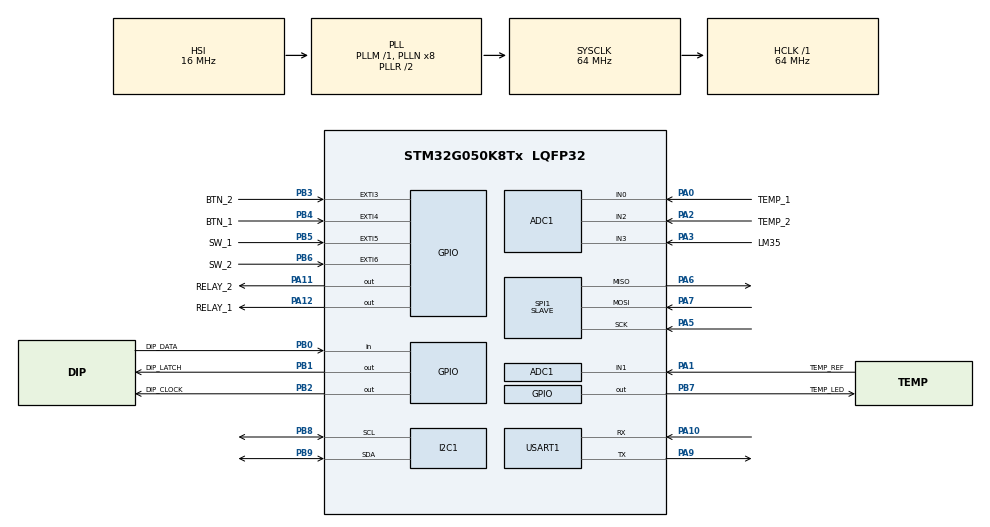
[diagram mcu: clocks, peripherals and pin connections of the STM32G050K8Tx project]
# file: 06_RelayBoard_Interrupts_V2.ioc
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ADC1.Channel-0\#ChannelRegularConversion=ADC_CHANNEL_0
ADC1.Channel-1\#ChannelRegularConversion=ADC_CHANNEL_1
ADC1.Channel-2\#ChannelRegularConversion=ADC_CHANNEL_2
ADC1.Channel-3\#ChannelRegularConversion=ADC_CHANNEL_3
ADC1.ClockPrescaler=ADC_CLOCK_ASYNC_DIV10
ADC1.NbrOfConversion=4
ADC1.NbrOfConversionFlag=1
ADC1.Rank-0\#ChannelRegularConversion=1
ADC1.Rank-1\#ChannelRegularConversion=2
ADC1.Rank-2\#ChannelRegularConversion=3
ADC1.Rank-3\#ChannelRegularConversion=4
ADC1.SamplingTime-0\#ChannelRegularConversion=ADC_SAMPLINGTIME_COMMON_1
ADC1.SamplingTime-1\#ChannelRegularConversion=ADC_SAMPLINGTIME_COMMON_1
ADC1.SamplingTime-2\#ChannelRegularConversion=ADC_SAMPLINGTIME_COMMON_1
ADC1.SamplingTime-3\#ChannelRegularConversion=ADC_SAMPLINGTIME_COMMON_1
ADC1.SelectedChannel=ADC_CHANNEL_0|ADC_CHANNEL_1|ADC_CHANNEL_2|ADC_CHANNEL_3
ADC1.TriggerFrequencyMode=ADC_TRIGGER_FREQ_LOW
ADC1.master=1
Dma.ADC1.0.Direction=DMA_PERIPH_TO_MEMORY
Dma.ADC1.0.EventEnable=DISABLE
Dma.ADC1.0.Instance=DMA1_Channel1
Dma.ADC1.0.MemDataAlignment=DMA_MDATAALIGN_WORD
Dma.ADC1.0.MemInc=DMA_MINC_ENABLE
Dma.ADC1.0.Mode=DMA_CIRCULAR
Dma.ADC1.0.PeriphDataAlignment=DMA_PDATAALIGN_WORD
Dma.ADC1.0.PeriphInc=DMA_PINC_DISABLE
Dma.ADC1.0.Polarity=HAL_DMAMUX_REQ_GEN_RISING
Dma.ADC1.0.Priority=DMA_PRIORITY_LOW
Dma.ADC1.0.RequestNumber=1
Dma.ADC1.0.SignalID=NONE
Dma.ADC1.0.SyncEnable=DISABLE
Dma.ADC1.0.SyncPolarity=HAL_DMAMUX_SYNC_NO_EVENT
Dma.ADC1.0.SyncRequestNumber=1
Dma.ADC1.0.SyncSignalID=NONE
Dma.Request0=ADC1
I2C1.Timing=0x10B17DB5
Mcu.Family=STM32G0
Mcu.Name=STM32G050K8Tx
Mcu.Package=LQFP32
NVIC.DMA1_Channel1_IRQn=true\:0\:0\:false\:false\:true\:false\:true\:true
NVIC.EXTI2_3_IRQn=true\:0\:0\:true\:false\:true\:true\:true\:true
NVIC.EXTI4_15_IRQn=true\:0\:0\:false\:false\:true\:true\:true\:true
PA0.GPIO_Label=TEMP_1
PA0.Mode=IN0
PA0.Signal=ADC1_IN0
PA1.GPIO_Label=TEMP_REF
PA1.Mode=IN1
PA1.Signal=ADC1_IN1
PA10.Mode=Asynchronous
PA10.Signal=USART1_RX
PA11\ [PA9].GPIO_Label=RELAY_2
PA11\ [PA9].Signal=GPIO_Output
PA12\ [PA10].GPIO_Label=RELAY_1
PA12\ [PA10].Signal=GPIO_Output
PA13.Mode=Serial_Wire
PA13.Signal=SYS_SWDIO
PA14-BOOT0.Mode=Serial_Wire
PA14-BOOT0.Signal=SYS_SWCLK
PA2.GPIO_Label=TEMP_2
PA2.Mode=IN2
PA2.Signal=ADC1_IN2
PA3.GPIO_Label=LM35
PA3.Mode=IN3
PA3.Signal=ADC1_IN3
PA5.Mode=Full_Duplex_Slave
PA5.Signal=SPI1_SCK
PA6.Mode=Full_Duplex_Slave
PA6.Signal=SPI1_MISO
PA7.Mode=Full_Duplex_Slave
PA7.Signal=SPI1_MOSI
PA9.Mode=Asynchronous
PA9.Signal=USART1_TX
PB0.GPIO_Label=DIP_DATA
PB0.Signal=GPIO_Input
PB1.GPIO_Label=DIP_LATCH
PB1.Signal=GPIO_Output
PB2.GPIO_Label=DIP_CLOCK
PB2.Signal=GPIO_Output
PB3.GPIO_Label=BTN_2
PB3.GPIO_ModeDefaultEXTI=GPIO_MODE_IT_FALLING
PB3.Signal=GPXTI3
PB4.GPIO_Label=BTN_1
PB4.GPIO_ModeDefaultEXTI=GPIO_MODE_IT_FALLING
PB4.Signal=GPXTI4
PB5.GPIO_Label=SW_1
PB5.GPIO_ModeDefaultEXTI=GPIO_MODE_IT_RISING_FALLING
PB5.Signal=GPXTI5
PB6.GPIO_Label=SW_2
PB6.GPIO_ModeDefaultEXTI=GPIO_MODE_IT_RISING_FALLING
PB6.Signal=GPXTI6
PB7.GPIO_Label=TEMP_LED
PB7.Signal=GPIO_Output
PB8.Mode=I2C
PB8.Signal=I2C1_SCL
PB9.Mode=I2C
PB9.Signal=I2C1_SDA
PC14-OSC32_IN\ (PC14).Mode=HSE-External-Clock-Source
PC14-OSC32_IN\ (PC14).Signal=RCC_OSC_IN
PC15-OSC32_OUT\ (PC15).Mode=OSC enable
PC15-OSC32_OUT\ (PC15).Signal=RCC_OSC_EN
ProjectManager.HeapSize=0x200
ProjectManager.StackSize=0x400
ProjectManager.TargetToolchain=CMake
RCC.ADCCLockSelection=RCC_ADCCLKSOURCE_HSI
RCC.ADCFreq_Value=16000000
RCC.AHBFreq_Value=64000000
RCC.CortexFreq_Value=64000000
RCC.EXTERNAL_CLOCK_VALUE=48000
RCC.HCLKFreq_Value=64000000
RCC.HSE_VALUE=8000000
RCC.HSI_VALUE=16000000
RCC.LSE_VALUE=32768
RCC.SYSCLKFreq_VALUE=64000000
RCC.SYSCLKSource=RCC_SYSCLKSOURCE_PLLCLK
RCC.VCOOutputFreq_Value=128000000
SPI1.Direction=SPI_DIRECTION_2LINES
SPI1.Mode=SPI_MODE_SLAVE
SPI1.VirtualType=VM_SLAVE
USART1.VirtualMode-Asynchronous=VM_ASYNC
VP_SYS_VS_DBSignals.Mode=DisableDeadBatterySignals
board=custom

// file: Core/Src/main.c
/* USER CODE BEGIN Header */
/**
  ******************************************************************************
  * @file           : main.c
  * @brief          : Main program body
  ******************************************************************************
  * @attention
  *
  * Copyright (c) 2025 STMicroelectronics.
  * All rights reserved.
  *
  * This software is licensed under terms that can be found in the LICENSE file
  * in the root directory of this software component.
  * If no LICENSE file comes with this software, it is provided AS-IS.
  *
  ******************************************************************************
  */
/* USER CODE END Header */
#include "main.h"
#include "adc.h"
#include "dma.h"
#include "i2c.h"
#include "spi.h"
#include "usart.h"
#include "gpio.h"

/* USER CODE BEGIN Includes */

#include "../../Drivers/Utility/config.h"
#include "../../Drivers/Utility/DIPs.h"
#include "../../Drivers/Utility/Inputs.h"

/* USER CODE END Includes */

void SystemClock_Config(void);

int main(void)
{

  /* MCU Configuration--------------------------------------------------------*/

  /* Reset of all peripherals, Initializes the Flash interface and the Systick. */
  HAL_Init();

  /* Configure the system clock */
  SystemClock_Config();

  /* Initialize all configured peripherals */
  MX_GPIO_Init();
  MX_DMA_Init();
  MX_ADC1_Init();
  MX_I2C1_Init();
  MX_SPI1_Init();
  MX_USART1_UART_Init();
  /* USER CODE BEGIN 2 */

  ReadDIPSwitch(&Timers_CfgParam.Relay1_Timer, &Timers_CfgParam.Relay2_Timer);

  /* USER CODE END 2 */

  /* Infinite loop */
  /* USER CODE BEGIN WHILE */
  while (1)
  {

    //HAL_GPIO_TogglePin(TEMP_LED_GPIO_Port, TEMP_LED_Pin);
    HAL_Delay(10);
    /* USER CODE END WHILE */

  }
}

void SystemClock_Config(void)
{
  RCC_OscInitTypeDef RCC_OscInitStruct = {0};
  RCC_ClkInitTypeDef RCC_ClkInitStruct = {0};

  /** Configure the main internal regulator output voltage
  */
  HAL_PWREx_ControlVoltageScaling(PWR_REGULATOR_VOLTAGE_SCALE1);

  /** Initializes the RCC Oscillators according to the specified parameters
  * in the RCC_OscInitTypeDef structure.
  */
  RCC_OscInitStruct.OscillatorType = RCC_OSCILLATORTYPE_HSI;
  RCC_OscInitStruct.HSIState = RCC_HSI_ON;
  RCC_OscInitStruct.HSIDiv = RCC_HSI_DIV1;
  RCC_OscInitStruct.HSICalibrationValue = RCC_HSICALIBRATION_DEFAULT;
  RCC_OscInitStruct.PLL.PLLState = RCC_PLL_ON;
  RCC_OscInitStruct.PLL.PLLSource = RCC_PLLSOURCE_HSI;
  RCC_OscInitStruct.PLL.PLLM = RCC_PLLM_DIV1;
  RCC_OscInitStruct.PLL.PLLN = 8;
  RCC_OscInitStruct.PLL.PLLP = RCC_PLLP_DIV2;
  RCC_OscInitStruct.PLL.PLLR = RCC_PLLR_DIV2;
  if (HAL_RCC_OscConfig(&RCC_OscInitStruct) != HAL_OK)
  {
    Error_Handler();
  }

  /** Initializes the CPU, AHB and APB buses clocks
  */
  RCC_ClkInitStruct.ClockType = RCC_CLOCKTYPE_HCLK|RCC_CLOCKTYPE_SYSCLK
                              |RCC_CLOCKTYPE_PCLK1;
  RCC_ClkInitStruct.SYSCLKSource = RCC_SYSCLKSOURCE_PLLCLK;
  RCC_ClkInitStruct.AHBCLKDivider = RCC_SYSCLK_DIV1;
  RCC_ClkInitStruct.APB1CLKDivider = RCC_HCLK_DIV1;

  if (HAL_RCC_ClockConfig(&RCC_ClkInitStruct, FLASH_LATENCY_2) != HAL_OK)
  {
    Error_Handler();
  }
}

void Error_Handler(void)
{
  __disable_irq();
  while (1)
  {
  }
}
